# PIC32CM6408MC00048 register map
Vendor: Microchip Technology; Series: PIC32CMMC00; File version: 0
CPU: CM0+ r0p0, little endian, MPU, no FPU, VTOR, 2 interrupt priority bits, 27 interrupts
Registers are 32-bit, read-write, reset 0x0 unless marked. A register's access mark holds for its fields unless they carry their own. Offsets are from the block's base; [hi:lo] are bit positions; {n}, {i} and the like mark numbered series; 'fields as' and 'values as' point back to an identical list.

## DAC — Digital Analog Converter
Base 0x42005400
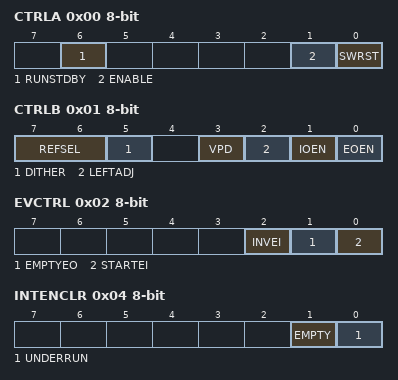
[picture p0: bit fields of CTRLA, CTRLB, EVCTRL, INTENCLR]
0x00 CTRLA 8-bit — Control A
  [6] RUNSTDBY — Run in Standby
  [1] ENABLE
  [0] SWRST — Software Reset
0x01 CTRLB 8-bit — Control B
  [7:6] REFSEL — Reference Selection
    0=INTREF (Internal Voltage Reference); 1=VDDANA (Analog Voltage Supply); 2=VREFA (External Voltage Reference A (shared with ADC))
  [5] DITHER — Dither Enable
  [3] VPD — Voltage Pump Disable
  [2] LEFTADJ — Left Adjusted Data
  [1] IOEN — Internal Output Enable
  [0] EOEN — External Output Enable
0x02 EVCTRL 8-bit — Event Control
  [2] INVEI — Invert Event Input
  [1] EMPTYEO — Data Buffer Empty Event Output
  [0] STARTEI — Start Conversion Event Input
0x04 INTENCLR 8-bit write-1-clears — Interrupt Enable Clear
  [1] EMPTY — Data Buffer Empty Interrupt Enable
  [0] UNDERRUN — Underrun Interrupt Enable
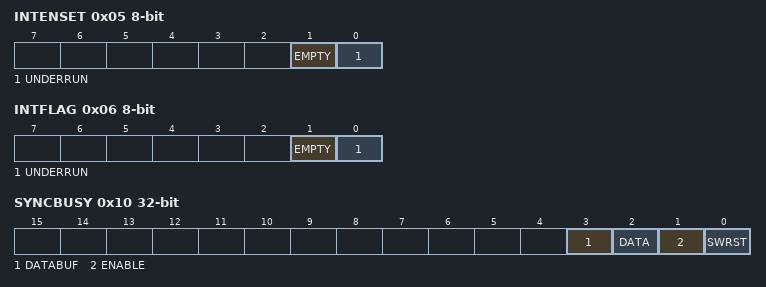
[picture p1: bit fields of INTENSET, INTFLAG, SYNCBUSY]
0x05 INTENSET 8-bit write-1-sets — Interrupt Enable Set
  fields as INTENCLR
0x06 INTFLAG 8-bit write-1-clears — Interrupt Flag Status and Clear
  [1] EMPTY — Data Buffer Empty
  [0] UNDERRUN
0x07 STATUS 8-bit ro
  [0] READY — DAC Ready
0x08 DATA 16-bit wo
  [15:0] DATA — Data value to be converted
0x0C DATABUF 16-bit wo — Data Buffer
0x10 SYNCBUSY ro — Synchronization Busy
  [3] DATABUF — Data Buffer
  [2] DATA
  [1] ENABLE — DAC Enable Status
  [0] SWRST — Software Reset
0x14 DBGCTRL 8-bit — Debug Control
  [0] DBGRUN — Debug Run

## DIVAS — Divide and Square Root Accelerator
Base 0x48000000
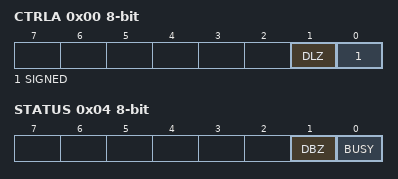
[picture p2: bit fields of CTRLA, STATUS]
0x00 CTRLA 8-bit — Control
  [1] DLZ — Disable Leading Zero Optimization
  [0] SIGNED
0x04 STATUS 8-bit
  [1] DBZ — Writing a one to this bit clears DBZ to zero
  [0] BUSY — DIVAS Accelerator Busy
0x08 DIVIDEND
0x0C DIVISOR
0x10 RESULT ro
0x14 REM ro — Remainder
0x18 SQRNUM — Square Root Input

## DSU — Device Service Unit
Base 0x41002000
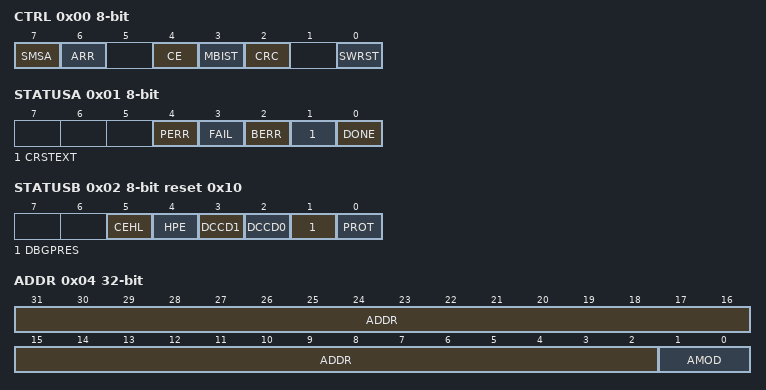
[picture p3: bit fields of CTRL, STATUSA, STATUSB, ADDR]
0x00 CTRL 8-bit wo — Control
  [7] SMSA — Start Memory Stream Access
  [6] ARR — Auxiliary Row Read
  [4] CE — Chip-Erase
  [3] MBIST — Memory built-in self-test
  [2] CRC — 32-bit Cyclic Redundancy Code
  [0] SWRST — Software Reset
0x01 STATUSA 8-bit
  [4] PERR — Protection Error
  [3] FAIL — Failure
  [2] BERR — Bus Error
  [1] CRSTEXT — CPU Reset Phase Extension
  [0] DONE
0x02 STATUSB 8-bit ro reset 0x10
  [5] CEHL — Chip Erase Hard Lock
  [4] HPE — Hot-Plugging Enable
  [3] DCCD1 — Debug Communication Channel 1 Dirty
  [2] DCCD0 — Debug Communication Channel 0 Dirty
  [1] DBGPRES — Debugger Present
  [0] PROT — Protected
0x03 STATUSC 8-bit ro
  [2:0] STATE
0x04 ADDR — Address
  [31:2] ADDR — Address
  [1:0] AMOD — Access Mode
0x08 LENGTH
  [31:2] LENGTH
0x0C DATA
{0x10+4i} DCC[{i}] (i=0..1) — Debug Communication Channel n
  [31:0] DATA
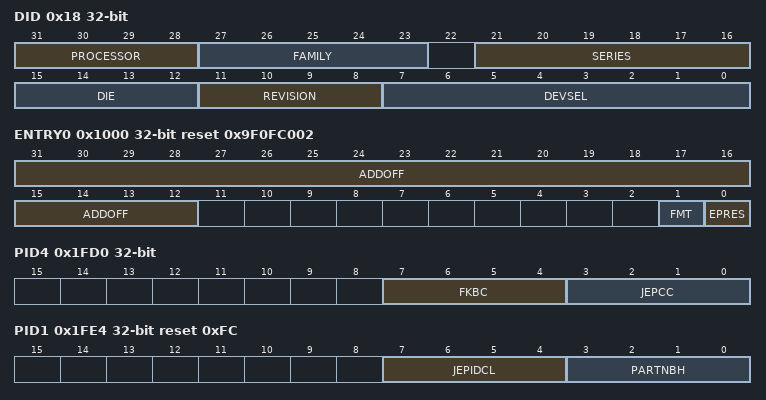
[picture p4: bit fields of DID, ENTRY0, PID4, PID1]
0x18 DID ro — Device Identification
  [31:28] PROCESSOR
    1=Cortex-M0+
  [27:23] FAMILY
    2=5V Industrial
  [21:16] SERIES
    6=MC00 (PIC32CM MC00)
  [15:12] DIE — Die Number
  [11:8] REVISION — Revision Number
  [7:0] DEVSEL — Device Select
    0=128KB_16KB_32PIN (128 KB Flash / 16 KB SRAM / 32-pin); 1=64KB_8KB_32PIN (64 KB Flash / 8 KB SRAM / 32-pin); 6=128KB_16KB_48PIN_CAN (128 KB Flash / 16 KB SRAM / 48-pin); 7=64KB_8KB_48PIN_CAN (64 KB Flash / 8 KB SRAM / 48-pin)
{0xF0+4i} DCFG[{i}] (i=0..1) — Device Configuration
  [31:0] DCFG
0x1000 ENTRY0 ro reset 0x9F0FC002 — CoreSight ROM Table Entry 0
  [31:12] ADDOFF — Address Offset
  [1] FMT — Format
  [0] EPRES — Entry Present
0x1004 ENTRY1 ro reset 0x5002 — CoreSight ROM Table Entry 1
0x1008 END ro — CoreSight ROM Table End
  [31:0] END — End Marker
0x1FCC MEMTYPE ro — CoreSight ROM Table Memory Type
  [0] SMEMP — System Memory Present
0x1FD0 PID4 ro — Peripheral Identification 4
  [7:4] FKBC — 4KB count
  [3:0] JEPCC — JEP-106 Continuation Code
{0x1FC0+4i} PID{i} ro (i=5..7) — Peripheral Identification {i}
0x1FE0 PID0 ro reset 0xD0 — Peripheral Identification 0
  [7:0] PARTNBL — Part Number Low
0x1FE4 PID1 ro reset 0xFC — Peripheral Identification 1
  [7:4] JEPIDCL — Low part of the JEP-106 Identity Code
  [3:0] PARTNBH — Part Number High
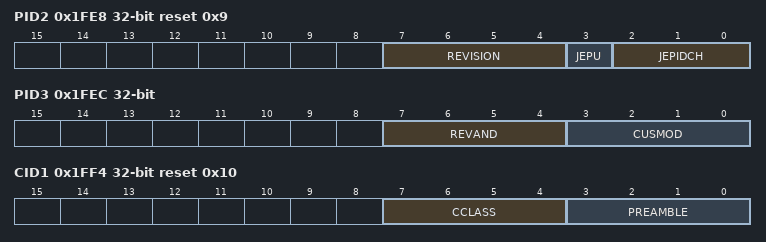
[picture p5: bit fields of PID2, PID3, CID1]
0x1FE8 PID2 ro reset 0x9 — Peripheral Identification 2
  [7:4] REVISION — Revision Number
  [3] JEPU — JEP-106 Identity Code is used
  [2:0] JEPIDCH — JEP-106 Identity Code High
0x1FEC PID3 ro — Peripheral Identification 3
  [7:4] REVAND — Revision Number
  [3:0] CUSMOD — ARM CUSMOD
0x1FF0 CID0 ro reset 0xD — Component Identification 0
  [7:0] PREAMBLEB0 — Preamble Byte 0
0x1FF4 CID1 ro reset 0x10 — Component Identification 1
  [7:4] CCLASS — Component Class
  [3:0] PREAMBLE
0x1FF8 CID2 ro reset 0x5 — Component Identification 2
  [7:0] PREAMBLEB2 — Preamble Byte 2
0x1FFC CID3 ro reset 0xB1 — Component Identification 3
  [7:0] PREAMBLEB3 — Preamble Byte 3

## Notices in the file
Copyright (c) 2026 Microchip Technology Inc.
SPDX-License-Identifier: Apache-2.0
Licensed under the Apache License, Version 2.0 (the "License");
you may not use this file except in compliance with the License.
You may obtain a copy of the License at
http://www.apache.org/licenses/LICENSE-2.0
Unless required by applicable law or agreed to in writing, software
distributed under the License is distributed on an "AS IS" BASIS,
WITHOUT WARRANTIES OR CONDITIONS OF ANY KIND, either express or implied.
See the License for the specific language governing permissions and
limitations under the License.
